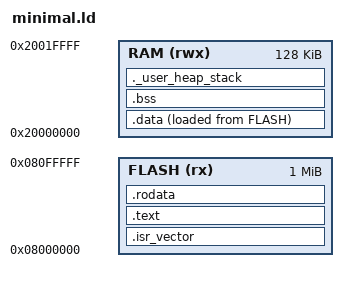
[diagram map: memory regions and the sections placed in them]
/**
 * @file minimal.ld
 * @brief Minimal linker script for QEMU testing
 */

ENTRY(Reset_Handler)

MEMORY
{
    FLASH (rx) : ORIGIN = 0x08000000, LENGTH = 1024K
    RAM (rwx)  : ORIGIN = 0x20000000, LENGTH = 128K
}

SECTIONS
{
    .isr_vector :
    {
        . = ALIGN(4);
        KEEP(*(.isr_vector))
        . = ALIGN(4);
    } >FLASH

    .text :
    {
        . = ALIGN(4);
        *(.text)
        *(.text*)
        . = ALIGN(4);
    } >FLASH

    .rodata :
    {
        . = ALIGN(4);
        *(.rodata)
        *(.rodata*)
        . = ALIGN(4);
    } >FLASH

    .data :
    {
        . = ALIGN(4);
        _sdata = .;
        *(.data)
        *(.data*)
        . = ALIGN(4);
        _edata = .;
    } >RAM AT> FLASH

    .bss :
    {
        . = ALIGN(4);
        _sbss = .;
        *(.bss)
        *(.bss*)
        *(COMMON)
        . = ALIGN(4);
        _ebss = .;
    } >RAM

    /* Stack */
    ._user_heap_stack :
    {
        . = ALIGN(8);
        PROVIDE ( end = . );
        PROVIDE ( _end = . );
        . = . + 0x400;  /* Minimum stack size */
        . = ALIGN(8);
    } >RAM
}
